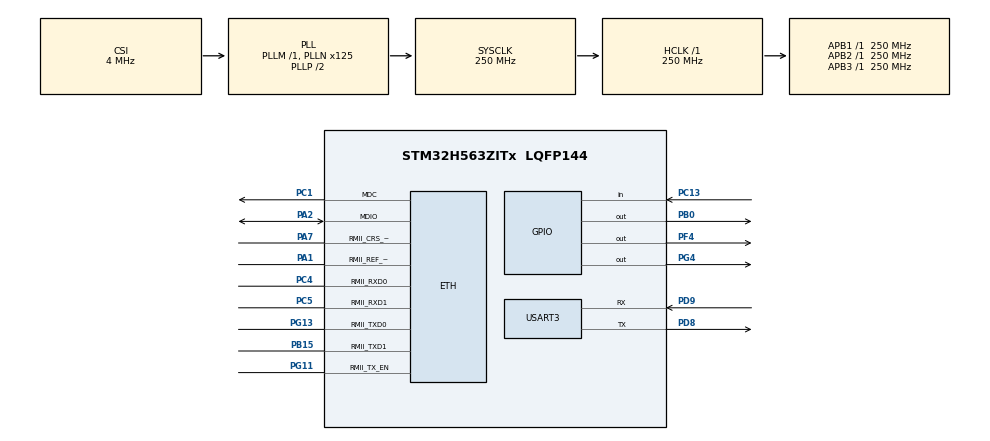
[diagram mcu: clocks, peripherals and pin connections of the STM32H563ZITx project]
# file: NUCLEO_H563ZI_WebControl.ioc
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BOOTPATH.BootPathName=LEGACY
BOOTPATH.UserSelectedBootPath=LEGACY
CORTEX_M33_NS.Number-Cortex_Memory_Protection_Unit_Region0_OTP_RO_AREAS_Settings=MPU_REGION_NUMBER0
CORTEX_M33_NS.default_mode_Activation=1
CORTEX_M33_NS.userName=CORTEX_M33
ETH.MediaInterface=HAL_ETH_RMII_MODE
Mcu.Family=STM32H5
Mcu.Name=STM32H563ZITx
Mcu.Package=LQFP144
NVIC.PriorityGroup=NVIC_PRIORITYGROUP_4
PA1.Mode=RMII
PA1.Signal=ETH_RMII_REF_CLK
PA2.Mode=RMII
PA2.Signal=ETH_MDIO
PA7.Mode=RMII
PA7.Signal=ETH_RMII_CRS_DV
PB0.Signal=GPIO_Output
PB15.Mode=RMII
PB15.Signal=ETH_RMII_TXD1
PC1.Mode=RMII
PC1.Signal=ETH_MDC
PC13.Signal=GPIO_Input
PC4.Mode=RMII
PC4.Signal=ETH_RMII_RXD0
PC5.Mode=RMII
PC5.Signal=ETH_RMII_RXD1
PD8.Mode=Asynchronous
PD8.Signal=USART3_TX
PD9.Mode=Asynchronous
PD9.Signal=USART3_RX
PF4.Signal=GPIO_Output
PG11.Mode=RMII
PG11.Signal=ETH_RMII_TX_EN
PG13.Mode=RMII
PG13.Signal=ETH_RMII_TXD0
PG4.Signal=GPIO_Output
ProjectManager.HeapSize=0x10000
ProjectManager.StackSize=0x2000
ProjectManager.TargetToolchain=CMake
RCC.ADCFreq_Value=250000000
RCC.AHBFreq_Value=250000000
RCC.APB1Freq_Value=250000000
RCC.APB1TimFreq_Value=250000000
RCC.APB2Freq_Value=250000000
RCC.APB2TimFreq_Value=250000000
RCC.APB3Freq_Value=250000000
RCC.CSI_VALUE=4000000
RCC.CortexFreq_Value=250000000
RCC.EPOD_VALUE=4000000
RCC.HCLKFreq_Value=250000000
RCC.HSE_VALUE=25000000
RCC.HSI48_VALUE=48000000
RCC.HSI_VALUE=64000000
RCC.LSE_VALUE=32768
RCC.LSIRC_VALUE=32000
RCC.PLL2FRACN=0
RCC.PLL3FRACN=0
RCC.PLLFRACN=0
RCC.PLLN=125
RCC.SYSCLKFreq_VALUE=250000000
RCC.SYSCLKSource=RCC_SYSCLKSOURCE_PLLCLK
RCC.USBFreq_Value=48000000
RCC.VCOOutputFreq_Value=500000000
USART3.VirtualMode-Asynchronous=VM_ASYNC
VP_BOOTPATH_VS_BOOTPATH.Mode=BP_Activate
VP_CORTEX_M33_NS_VS_Hclk.Mode=Hclk_Mode
VP_ICACHE_VS_ENABLE_ICACHE_MEMORY.Mode=Memoryregions
VP_ICACHE_VS_ICACHE.Mode=DirectMappedCache
VP_MEMORYMAP_VS_MEMORYMAP.Mode=CurAppReg
VP_PWR_VS_LPOM.Mode=PowerOptimisation
VP_PWR_VS_SECSignals.Mode=Security/Privilege
VP_RNG_VS_RNG.Mode=RNG_Activate
board=custom

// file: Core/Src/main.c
/* USER CODE BEGIN Header */
/**
  ******************************************************************************
  * @file           : main.c
  * @brief          : Main program body
  ******************************************************************************
  * @attention
  *
  * Copyright (c) 2026 STMicroelectronics.
  * All rights reserved.
  *
  * This software is licensed under terms that can be found in the LICENSE file
  * in the root directory of this software component.
  * If no LICENSE file comes with this software, it is provided AS-IS.
  *
  ******************************************************************************
  */
/* USER CODE END Header */
#include "main.h"
#include "string.h"

/* USER CODE BEGIN Includes */
#include "app.h"

/* USER CODE END Includes */

ETH_TxPacketConfigTypeDef TxConfig;
ETH_DMADescTypeDef  DMARxDscrTab[ETH_RX_DESC_CNT]; /* Ethernet Rx DMA Descriptors */
ETH_DMADescTypeDef  DMATxDscrTab[ETH_TX_DESC_CNT]; /* Ethernet Tx DMA Descriptors */

ETH_HandleTypeDef heth;

RNG_HandleTypeDef hrng;

UART_HandleTypeDef huart3;

void SystemClock_Config(void);
static void MPU_Config(void);
static void MX_GPIO_Init(void);
static void MX_ICACHE_Init(void);
static void MX_RNG_Init(void);
static void MX_USART3_UART_Init(void);

int main(void)
{

  /* USER CODE BEGIN 1 */

#define MX_ETH_Init() App_EthernetInit()

  /* USER CODE END 1 */

  /* MCU Configuration--------------------------------------------------------*/

  /* MPU Configuration--------------------------------------------------------*/
  MPU_Config();

  /* Reset of all peripherals, Initializes the Flash interface and the Systick. */
  HAL_Init();

  /* Configure the system clock */
  SystemClock_Config();

  /* Initialize all configured peripherals */
  MX_GPIO_Init();
  MX_ETH_Init();
  MX_ICACHE_Init();
  MX_RNG_Init();
  MX_USART3_UART_Init();
  /* USER CODE BEGIN 2 */

#undef MX_ETH_Init
  App_Init();

  /* USER CODE END 2 */

  /* Infinite loop */
  /* USER CODE BEGIN WHILE */
  while (1)
  {
    App_Poll();
    /* USER CODE END WHILE */

  }
}

void SystemClock_Config(void)
{
  RCC_OscInitTypeDef RCC_OscInitStruct = {0};
  RCC_ClkInitTypeDef RCC_ClkInitStruct = {0};

  /** Configure the main internal regulator output voltage
  */
  __HAL_PWR_VOLTAGESCALING_CONFIG(PWR_REGULATOR_VOLTAGE_SCALE0);

  while(!__HAL_PWR_GET_FLAG(PWR_FLAG_VOSRDY)) {}

  /** Initializes the RCC Oscillators according to the specified parameters
  * in the RCC_OscInitTypeDef structure.
  */
  RCC_OscInitStruct.OscillatorType = RCC_OSCILLATORTYPE_HSI48|RCC_OSCILLATORTYPE_CSI;
  RCC_OscInitStruct.HSI48State = RCC_HSI48_ON;
  RCC_OscInitStruct.CSIState = RCC_CSI_ON;
  RCC_OscInitStruct.CSICalibrationValue = RCC_CSICALIBRATION_DEFAULT;
  RCC_OscInitStruct.PLL.PLLState = RCC_PLL_ON;
  RCC_OscInitStruct.PLL.PLLSource = RCC_PLL1_SOURCE_CSI;
  RCC_OscInitStruct.PLL.PLLM = 1;
  RCC_OscInitStruct.PLL.PLLN = 125;
  RCC_OscInitStruct.PLL.PLLP = 2;
  RCC_OscInitStruct.PLL.PLLQ = 2;
  RCC_OscInitStruct.PLL.PLLR = 2;
  RCC_OscInitStruct.PLL.PLLRGE = RCC_PLL1_VCIRANGE_2;
  RCC_OscInitStruct.PLL.PLLVCOSEL = RCC_PLL1_VCORANGE_WIDE;
  RCC_OscInitStruct.PLL.PLLFRACN = 0;
  if (HAL_RCC_OscConfig(&RCC_OscInitStruct) != HAL_OK)
  {
    Error_Handler();
  }

  /** Initializes the CPU, AHB and APB buses clocks
  */
  RCC_ClkInitStruct.ClockType = RCC_CLOCKTYPE_HCLK|RCC_CLOCKTYPE_SYSCLK
                              |RCC_CLOCKTYPE_PCLK1|RCC_CLOCKTYPE_PCLK2
                              |RCC_CLOCKTYPE_PCLK3;
  RCC_ClkInitStruct.SYSCLKSource = RCC_SYSCLKSOURCE_PLLCLK;
  RCC_ClkInitStruct.AHBCLKDivider = RCC_SYSCLK_DIV1;
  RCC_ClkInitStruct.APB1CLKDivider = RCC_HCLK_DIV1;
  RCC_ClkInitStruct.APB2CLKDivider = RCC_HCLK_DIV1;
  RCC_ClkInitStruct.APB3CLKDivider = RCC_HCLK_DIV1;

  if (HAL_RCC_ClockConfig(&RCC_ClkInitStruct, FLASH_LATENCY_5) != HAL_OK)
  {
    Error_Handler();
  }

  /** Configure the programming delay
  */
  __HAL_FLASH_SET_PROGRAM_DELAY(FLASH_PROGRAMMING_DELAY_2);
}

void MX_ETH_Init(void)
{

   static uint8_t MACAddr[6];

  heth.Instance = ETH;
  MACAddr[0] = 0x00;
  MACAddr[1] = 0x80;
  MACAddr[2] = 0xE1;
  MACAddr[3] = 0x00;
  MACAddr[4] = 0x00;
  MACAddr[5] = 0x00;
  heth.Init.MACAddr = &MACAddr[0];
  heth.Init.MediaInterface = HAL_ETH_RMII_MODE;
  heth.Init.TxDesc = DMATxDscrTab;
  heth.Init.RxDesc = DMARxDscrTab;
  heth.Init.RxBuffLen = 1524;

  if (HAL_ETH_Init(&heth) != HAL_OK)
  {
    Error_Handler();
  }

  memset(&TxConfig, 0 , sizeof(ETH_TxPacketConfigTypeDef));
  TxConfig.Attributes = ETH_TX_PACKETS_FEATURES_CSUM | ETH_TX_PACKETS_FEATURES_CRCPAD;
  TxConfig.ChecksumCtrl = ETH_CHECKSUM_IPHDR_PAYLOAD_INSERT_PHDR_CALC;
  TxConfig.CRCPadCtrl = ETH_CRC_PAD_INSERT;

}

static void MX_ICACHE_Init(void)
{

  /** Enable instruction cache in 1-way (direct mapped cache)
  */
  if (HAL_ICACHE_ConfigAssociativityMode(ICACHE_1WAY) != HAL_OK)
  {
    Error_Handler();
  }
  if (HAL_ICACHE_Enable() != HAL_OK)
  {
    Error_Handler();
  }

}

static void MX_RNG_Init(void)
{

  hrng.Instance = RNG;
  hrng.Init.ClockErrorDetection = RNG_CED_ENABLE;
  if (HAL_RNG_Init(&hrng) != HAL_OK)
  {
    Error_Handler();
  }

}

static void MX_USART3_UART_Init(void)
{

  huart3.Instance = USART3;
  huart3.Init.BaudRate = 115200;
  huart3.Init.WordLength = UART_WORDLENGTH_8B;
  huart3.Init.StopBits = UART_STOPBITS_1;
  huart3.Init.Parity = UART_PARITY_NONE;
  huart3.Init.Mode = UART_MODE_TX_RX;
  huart3.Init.HwFlowCtl = UART_HWCONTROL_NONE;
  huart3.Init.OverSampling = UART_OVERSAMPLING_16;
  huart3.Init.OneBitSampling = UART_ONE_BIT_SAMPLE_DISABLE;
  huart3.Init.ClockPrescaler = UART_PRESCALER_DIV1;
  huart3.AdvancedInit.AdvFeatureInit = UART_ADVFEATURE_NO_INIT;
  if (HAL_UART_Init(&huart3) != HAL_OK)
  {
    Error_Handler();
  }
  if (HAL_UARTEx_SetTxFifoThreshold(&huart3, UART_TXFIFO_THRESHOLD_1_8) != HAL_OK)
  {
    Error_Handler();
  }
  if (HAL_UARTEx_SetRxFifoThreshold(&huart3, UART_RXFIFO_THRESHOLD_1_8) != HAL_OK)
  {
    Error_Handler();
  }
  if (HAL_UARTEx_DisableFifoMode(&huart3) != HAL_OK)
  {
    Error_Handler();
  }

}

static void MX_GPIO_Init(void)
{
  GPIO_InitTypeDef GPIO_InitStruct = {0};

  /* GPIO Ports Clock Enable */
  __HAL_RCC_GPIOC_CLK_ENABLE();
  __HAL_RCC_GPIOF_CLK_ENABLE();
  __HAL_RCC_GPIOA_CLK_ENABLE();
  __HAL_RCC_GPIOB_CLK_ENABLE();
  __HAL_RCC_GPIOD_CLK_ENABLE();
  __HAL_RCC_GPIOG_CLK_ENABLE();

  /*Configure GPIO pin Output Level */
  HAL_GPIO_WritePin(GPIOF, GPIO_PIN_4, GPIO_PIN_RESET);

  /*Configure GPIO pin Output Level */
  HAL_GPIO_WritePin(GPIOB, GPIO_PIN_0, GPIO_PIN_RESET);

  /*Configure GPIO pin Output Level */
  HAL_GPIO_WritePin(GPIOG, GPIO_PIN_4, GPIO_PIN_RESET);

  /*Configure GPIO pin : PC13 */
  GPIO_InitStruct.Pin = GPIO_PIN_13;
  GPIO_InitStruct.Mode = GPIO_MODE_INPUT;
  GPIO_InitStruct.Pull = GPIO_NOPULL;
  HAL_GPIO_Init(GPIOC, &GPIO_InitStruct);

  /*Configure GPIO pin : PF4 */
  GPIO_InitStruct.Pin = GPIO_PIN_4;
  GPIO_InitStruct.Mode = GPIO_MODE_OUTPUT_PP;
  GPIO_InitStruct.Pull = GPIO_NOPULL;
  GPIO_InitStruct.Speed = GPIO_SPEED_FREQ_LOW;
  HAL_GPIO_Init(GPIOF, &GPIO_InitStruct);

  /*Configure GPIO pin : PB0 */
  GPIO_InitStruct.Pin = GPIO_PIN_0;
  GPIO_InitStruct.Mode = GPIO_MODE_OUTPUT_PP;
  GPIO_InitStruct.Pull = GPIO_NOPULL;
  GPIO_InitStruct.Speed = GPIO_SPEED_FREQ_LOW;
  HAL_GPIO_Init(GPIOB, &GPIO_InitStruct);

  /*Configure GPIO pin : PG4 */
  GPIO_InitStruct.Pin = GPIO_PIN_4;
  GPIO_InitStruct.Mode = GPIO_MODE_OUTPUT_PP;
  GPIO_InitStruct.Pull = GPIO_NOPULL;
  GPIO_InitStruct.Speed = GPIO_SPEED_FREQ_LOW;
  HAL_GPIO_Init(GPIOG, &GPIO_InitStruct);

}

 /* MPU Configuration */

void MPU_Config(void)
{
  MPU_Region_InitTypeDef MPU_InitStruct = {0};
  MPU_Attributes_InitTypeDef MPU_AttributesInit = {0};

  /* Disables the MPU */
  HAL_MPU_Disable();

  /** Initializes and configures the Region 0 and the memory to be protected
  */
  MPU_InitStruct.Enable = MPU_REGION_ENABLE;
  MPU_InitStruct.Number = MPU_REGION_NUMBER0;
  MPU_InitStruct.BaseAddress = 0x08FFF000;
  MPU_InitStruct.LimitAddress = 0x08FFFFFF;
  MPU_InitStruct.AttributesIndex = MPU_ATTRIBUTES_NUMBER0;
  MPU_InitStruct.AccessPermission = MPU_REGION_ALL_RO;
  MPU_InitStruct.DisableExec = MPU_INSTRUCTION_ACCESS_DISABLE;
  MPU_InitStruct.IsShareable = MPU_ACCESS_NOT_SHAREABLE;

  HAL_MPU_ConfigRegion(&MPU_InitStruct);

  /** Initializes and configures the Attribute 0 and the memory to be protected
  */
  MPU_AttributesInit.Number = MPU_ATTRIBUTES_NUMBER0;
  MPU_AttributesInit.Attributes = INNER_OUTER(MPU_NOT_CACHEABLE);

  HAL_MPU_ConfigMemoryAttributes(&MPU_AttributesInit);
  /* Enables the MPU */
  HAL_MPU_Enable(MPU_PRIVILEGED_DEFAULT);

}

void Error_Handler(void)
{
  __disable_irq();
  while (1)
  {
  }
}
